# AE1C1F4051920PH0_CM55_HE_View register map
Vendor: Alif Semiconductor; Series: E1; File version: 1.0
CPU: CM55 r1p0, selectable endian, MPU, FPU, double-precision FPU, DSP, VTOR, 8 interrupt priority bits, 1 SAU regions
Registers are 32-bit, read-write, reset 0x0 unless marked. A register's access mark holds for its fields unless they carry their own. Offsets are from the block's base; [hi:lo] are bit positions; lines under a group give offsets from that group; {n}, {i} and the like mark numbered series; 'fields as' and 'values as' point back to an identical list.

## LPGPIO_CTRL
Base 0x42007000
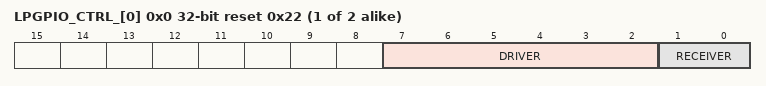
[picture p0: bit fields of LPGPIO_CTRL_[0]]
{0x0+4i} LPGPIO_CTRL_[{i}] (i=0..1) reset 0x22 — LPGPIO I/O Buffer Control Register
  [7:2] DRIVER — Driver configuration - Bit[7] selects driver mode: 0x0: Push-pull 0x1: Open drain - Bits[6-5] select driver strength: 0x0: 2 mA 0x1: 4 mA (default) 0x2: 8 mA 0x3: 12 mA - Bits[4-3] select driver disabled state: 0x0: Hi-Z 0x1: Pull-up 0x2: Pull-down 0x3: Bus keeper - Bit[2] selects slew rate: Note: Applicable only to 1.8-V I/Os (non-Flex) 0x0: Slow 0x1: Fast
  [1:0] RECEIVER — Receiver configuration - Bit[1] Schmitt trigger (hysteresis) enable: 0x0: Disabled 0x1: Enabled - Bit[0] receiver enable: 0x0: Disabled 0x1: Enabled

## M55HE_CFG
Base 0x43007000
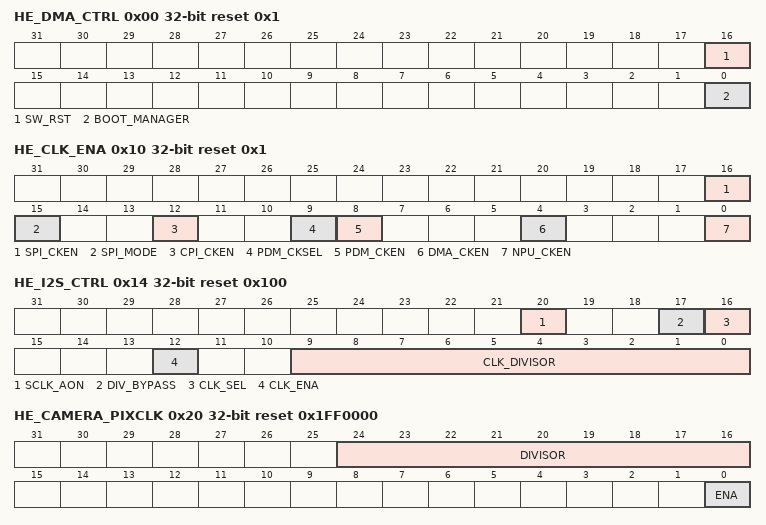
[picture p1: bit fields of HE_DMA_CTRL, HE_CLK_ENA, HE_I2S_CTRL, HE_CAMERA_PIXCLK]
0x00 HE_DMA_CTRL reset 0x1 — DMA2 Boot Control Register
  [16] SW_RST wo — Software reset for DMA2
    0=No reset; 1=Reset DMA2. This bit is self-cleared.
  [0] BOOT_MANAGER — When DMA2 exits from reset, this bit controls the security state of the DMA manager thread
    0=Assigns DMA manager to the secure state; 1=Assigns DMA manager to the non-secure state
0x04 HE_DMA_IRQ reset 0xFFFFFFFF — DMA2 Boot IRQ Non-Secure Register
  [31:0] BOOT_IRQ — Controls the security state of an event-interrupt resource, when DMA2 exits from reset
    0=DMA2 assigns event x or IRQ[x] to the secure state; 1=DMA2 assigns event x or IRQ[x] to the non-secure state
0x08 HE_DMA_PERIPH reset 0xFFFFFFFF — DMA2 Boot Peripheral Non-Secure Register
  [31:0] BOOT_PERIPH — Controls the security state of a peripheral request interface, when DMA2 exits from reset
    0=DMA2 assigns peripheral request interface x to the secure state; 1=DMA2 assigns peripheral request interface x to the non-secure state
0x0C HE_DMA_SEL — DMA2 Select Register
  [5:4] SPI — Select DMA for LPSPI0 and LPSPI1
    0=Select DMA2 group 1; 1=Select DMA2 group 2; 2=Select DMA2 group 2; 3=Select DMA2 group 2
0x10 HE_CLK_ENA reset 0x1 — Peripheral Clock Enable Register
  [16] SPI_CKEN — Enable clock for LPSPI0/1
    0=Disable clock; 1=Enable clock
  [15] SPI_MODE — Master/Slave mode select for LPSPI
    0=Master mode (LPSPI0); 1=Slave mode (LPSPI1)
  [12] CPI_CKEN — Enable clock for LPCPI
    0=Disable clock; 1=Enable clock
  [9] PDM_CKSEL — Select clock source for LPPDM
    0=Select 76.8 MHz crystal-oscillator clock (76M8_CLK); 1=Select audio PLL clock (AUDIO_PLL_CLK)
  [8] PDM_CKEN — Enable clock for LPPDM
    0=Disable clock; 1=Enable clock
  [4] DMA_CKEN — Enable clock for DMA2 and EVTRTR2
    0=Disable clock; 1=Enable clock
  [0] NPU_CKEN — Enable clock for NPU-HE
    0=Disable clock; 1=Enable clock
0x14 HE_I2S_CTRL reset 0x100 — LPI2S Control Register
  [20] SCLK_AON — LPI2S clock output to external device always on
    0=LPI2S clock output (LPI2S_SCLK) in gated mode; 1=LPI2S clock output (LPI2S_SCLK) in always on mode
  [17] DIV_BYPASS — LPI2S clock divider bypass
    0=Do not bypass clock divider; 1=Bypass clock divider
  [16] CLK_SEL — LPI2S functional clock source select
    values as HE_CLK_ENA.PDM_CKSEL
  [12] CLK_ENA — LPI2S clock enable
    0=Disable clock for LPI2S module; 1=Enable clock for LPI2S module
  [9:0] CLK_DIVISOR — LPI2S functional clock divisor n: Clock divided by n
    0=Illegal values; 1=Illegal values; 2=Clock divided by 2; 3=Clock divided by 3
0x20 HE_CAMERA_PIXCLK reset 0x1FF0000 — LPCPI Pixel Clock Control Register
  [24:16] DIVISOR — LPCPI pixel clock integer divisor n: Clock divided by n
    values as HE_I2S_CTRL.CLK_DIVISOR
  [0] ENA — LPCPI pixel clock enable
    0=Clock disabled; 1=Clock enabled
0x24 HE_FLT_ENA0 — Filter Enable 0 Register
  [31:0] FLT_ENA — For each bit:
    0=Disable glitch-filter for GPIO input; 1=Enable glitch-filter for GPIO input
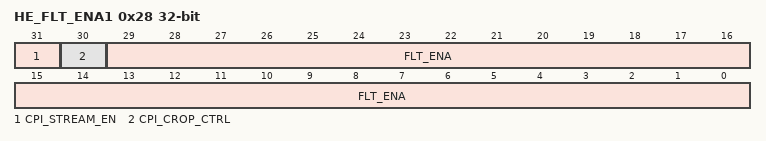
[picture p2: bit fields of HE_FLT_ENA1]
0x28 HE_FLT_ENA1 — Filter Enable 1 and LPCPI Control Register
  [31] CPI_STREAM_EN — LPCPI streaming feature control:
    0=Disable streaming; 1=Enable streaming
  [30] CPI_CROP_CTRL — LPCPI cropping feature control:
    0=Enable vertical-only cropping; 1=Enable vertical and horizontal cropping
  [29:0] FLT_ENA — For each bit: Note: Bits [29-10] are not used. Bits [7-0] are Reserved.
    0=Disable glitch-filter for LPGPIO input; 1=Enable glitch-filter for LPGPIO input
